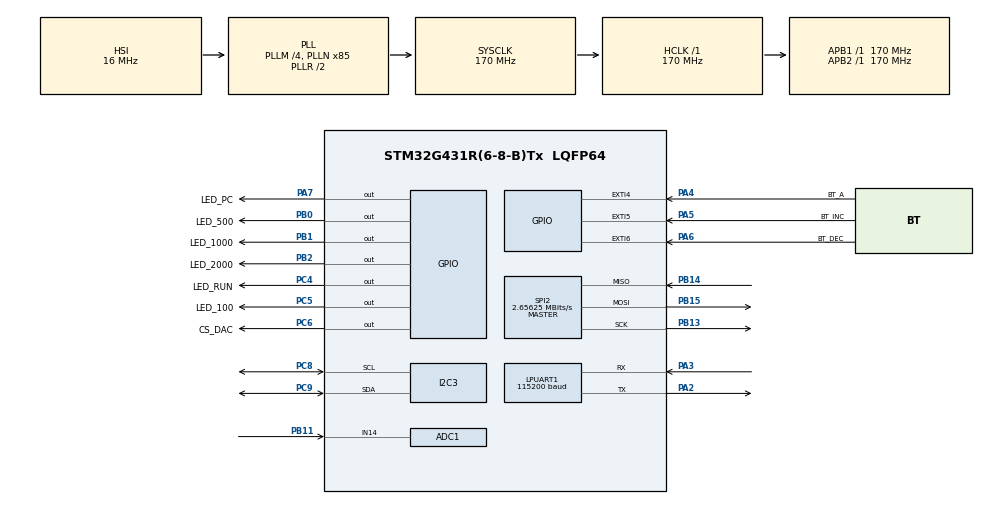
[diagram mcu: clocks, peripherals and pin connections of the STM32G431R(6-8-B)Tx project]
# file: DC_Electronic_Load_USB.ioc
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Mcu.Family=STM32G4
VP_SYS_VS_tim6.Mode=TIM6
RCC.CortexFreq_Value=170000000
SPI2.VirtualType=VM_MASTER
NVIC.TIM6_DAC_IRQn=true\:0\:0\:false\:false\:true\:false\:false\:true
Dma.LPUART1_TX.0.Mode=DMA_NORMAL
PC6.GPIO_Label=CS_DAC
PA6.GPIO_Label=BT_DEC
PB0.GPIO_Label=LED_500
PB11.Signal=ADC1_IN14
PB15.Signal=SPI2_MOSI
PB13.Signal=SPI2_SCK
Dma.LPUART1_TX.0.SyncPolarity=HAL_DMAMUX_SYNC_NO_EVENT
RCC.SYSCLKSource=RCC_SYSCLKSOURCE_PLLCLK
ProjectManager.StackSize=0x400
VP_FREERTOS_VS_CMSIS_V2.Mode=CMSIS_V2
Dma.LPUART1_TX.0.PeriphDataAlignment=DMA_PDATAALIGN_BYTE
Dma.LPUART1_TX.0.Direction=DMA_MEMORY_TO_PERIPH
NVIC.LPUART1_IRQn=true\:5\:0\:false\:false\:true\:true\:true\:true
RCC.HCLKFreq_Value=170000000
RCC.APB2TimFreq_Value=170000000
RCC.AHBFreq_Value=170000000
SPI2.BaudRatePrescaler=SPI_BAUDRATEPRESCALER_64
ADC1.Channel-0\#ChannelRegularConversion=ADC_CHANNEL_14
RCC.HSE_VALUE=8000000
Dma.LPUART1_TX.0.Polarity=HAL_DMAMUX_REQ_GEN_RISING
PB2.Signal=GPIO_Output
PB3.Mode=Trace_Asynchronous_SW
Dma.LPUART1_TX.0.MemInc=DMA_MINC_ENABLE
RCC.ADC12Freq_Value=170000000
PC14-OSC32_IN.Mode=LSE-External-Oscillator
PC4.GPIO_Label=LED_RUN
PA14.Mode=Trace_Asynchronous_SW
PB14.Mode=Full_Duplex_Master
PB1.GPIO_Label=LED_1000
PC9.Mode=I2C
SPI2.CalculateBaudRate=2.65625 MBits/s
VP_SYS_VS_DBSignals.Mode=DisableDeadBatterySignals
Dma.LPUART1_TX.0.Priority=DMA_PRIORITY_LOW
Dma.LPUART1_TX.0.SyncEnable=DISABLE
ADC1.SamplingTime-0\#ChannelRegularConversion=ADC_SAMPLETIME_2CYCLES_5
FREERTOS.configTOTAL_HEAP_SIZE=16384
Dma.LPUART1_TX.0.PeriphInc=DMA_PINC_DISABLE
Mcu.Package=LQFP64
PB1.Signal=GPIO_Output
PA6.Signal=GPXTI6
NVIC.TimeBase=TIM6_DAC_IRQn
SPI2.Mode=SPI_MODE_MASTER
NVIC.TimeBaseIP=TIM6
I2C3.Timing=0x30A0A7FB
RCC.APB1TimFreq_Value=170000000
FREERTOS.configUSE_TICK_HOOK=0
SPI2.Direction=SPI_DIRECTION_2LINES
PC5.Signal=GPIO_Output
PB13.Mode=Full_Duplex_Master
FREERTOS.configMAX_TASK_NAME_LEN=32
Dma.Request0=LPUART1_TX
PA4.GPIO_Label=BT_A
Dma.LPUART1_TX.0.SignalID=NONE
RCC.HSI48_VALUE=48000000
PA3.Signal=LPUART1_RX
Dma.LPUART1_TX.0.Instance=DMA1_Channel1
PC15-OSC32_OUT.Mode=LSE-External-Oscillator
NVIC.EXTI4_IRQn=true\:5\:0\:false\:false\:true\:true\:true\:true
PA5.GPIO_ModeDefaultEXTI=GPIO_MODE_IT_FALLING
PA6.GPIO_ModeDefaultEXTI=GPIO_MODE_IT_FALLING
FREERTOS.Tasks01=defaultTask,24,128,StartDefaultTask,As weak,NULL,Dynamic,NULL,NULL
ADC1.Rank-0\#ChannelRegularConversion=1
ADC1.OffsetNumber-0\#ChannelRegularConversion=ADC_OFFSET_NONE
PC8.Signal=I2C3_SCL
PC4.Signal=GPIO_Output
PC6.Signal=GPIO_Output
RCC.EXTERNAL_CLOCK_VALUE=12288000
PC14-OSC32_IN.Signal=RCC_OSC32_IN
Dma.LPUART1_TX.0.SyncSignalID=NONE
Dma.LPUART1_TX.0.RequestNumber=1
PA13.Signal=SYS_JTMS-SWDIO
PA3.Mode=Asynchronous
Dma.LPUART1_TX.0.EventEnable=DISABLE
PB11.Mode=IN14-Single-Ended
FREERTOS.configRECORD_STACK_HIGH_ADDRESS=1
ProjectManager.TargetToolchain=STM32CubeIDE
Dma.LPUART1_TX.0.SyncRequestNumber=1
PA4.GPIO_ModeDefaultEXTI=GPIO_MODE_IT_FALLING
RCC.USBFreq_Value=170000000
PC15-OSC32_OUT.Signal=RCC_OSC32_OUT
Dma.LPUART1_TX.0.MemDataAlignment=DMA_MDATAALIGN_BYTE
PB14.Signal=SPI2_MISO
PA5.Signal=GPXTI5
board=custom
RCC.VCOOutputFreq_Value=340000000
PB15.Mode=Full_Duplex_Master
RCC.APB2Freq_Value=170000000
PA13.Mode=Trace_Asynchronous_SW
Mcu.Name=STM32G431R(6-8-B)Tx
LPUART1.BaudRate=115200
PA2.Signal=LPUART1_TX
PC8.Mode=I2C
PB3.Signal=SYS_JTDO-SWO
PA4.Signal=GPXTI4
RCC.SYSCLKFreq_VALUE=170000000
PA7.GPIO_Label=LED_PC
ADC1.master=1
PA5.GPIO_Label=BT_INC
PC5.GPIO_Label=LED_100
NVIC.EXTI9_5_IRQn=true\:5\:0\:true\:false\:true\:true\:true\:true
PA14.Signal=SYS_JTCK-SWCLK
PB2.GPIO_Label=LED_2000
ProjectManager.HeapSize=0x200
RCC.HSI_VALUE=16000000
NVIC.PriorityGroup=NVIC_PRIORITYGROUP_4
ADC1.NbrOfConversionFlag=1
RCC.PLLM=RCC_PLLM_DIV4
RCC.PLLN=85
PA2.Mode=Asynchronous
SPI2.DataSize=SPI_DATASIZE_8BIT
PC9.Signal=I2C3_SDA
NVIC.DMA1_Channel1_IRQn=true\:5\:0\:false\:false\:true\:true\:false\:true
RCC.APB1Freq_Value=170000000
PB0.Signal=GPIO_Output
PA7.Signal=GPIO_Output

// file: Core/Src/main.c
/* USER CODE BEGIN Header */
/**
  ******************************************************************************
  * @file           : main.c
  * @brief          : Main program body
  ******************************************************************************
  * @attention
  *
  * <h2><center>&copy; Copyright (c) 2021 STMicroelectronics.
  * All rights reserved.</center></h2>
  *
  * This software component is licensed by ST under BSD 3-Clause license,
  * the "License"; You may not use this file except in compliance with the
  * License. You may obtain a copy of the License at:
  *                        opensource.org/licenses/BSD-3-Clause
  *
  ******************************************************************************
  */
/* USER CODE END Header */
#include "main.h"
#include "cmsis_os.h"

/* USER CODE BEGIN Includes */
#include "APP_Task.h"
/* USER CODE END Includes */

ADC_HandleTypeDef hadc1;

I2C_HandleTypeDef hi2c3;

UART_HandleTypeDef hlpuart1;
DMA_HandleTypeDef hdma_lpuart1_tx;

SPI_HandleTypeDef hspi2;

/* Definitions for defaultTask */
osThreadId_t defaultTaskHandle;
const osThreadAttr_t defaultTask_attributes = {
  .name = "defaultTask",
  .priority = (osPriority_t) osPriorityNormal,
  .stack_size = 128 * 4
};

void SystemClock_Config(void);
static void MX_GPIO_Init(void);
static void MX_DMA_Init(void);
static void MX_LPUART1_UART_Init(void);
static void MX_ADC1_Init(void);
static void MX_SPI2_Init(void);
static void MX_I2C3_Init(void);
void StartDefaultTask(void *argument);

int main(void)
{

  /* MCU Configuration--------------------------------------------------------*/

  /* Reset of all peripherals, Initializes the Flash interface and the Systick. */
  HAL_Init();

  /* Configure the system clock */
  SystemClock_Config();

  /* Initialize all configured peripherals */
  MX_GPIO_Init();
  MX_DMA_Init();
  MX_LPUART1_UART_Init();
  MX_ADC1_Init();
  MX_SPI2_Init();
  MX_I2C3_Init();

  /* Init scheduler */
  osKernelInitialize();

  /* Create the thread(s) */
  /* creation of defaultTask */
  defaultTaskHandle = osThreadNew(StartDefaultTask, NULL, &defaultTask_attributes);

  /* USER CODE BEGIN RTOS_THREADS */
  /* add threads, ... */
  mutex_creation();
  task_creation();
  /* USER CODE END RTOS_THREADS */

  /* Start scheduler */
  osKernelStart();

  /* We should never get here as control is now taken by the scheduler */
  /* Infinite loop */
  while (1)
  {

  }
}

void SystemClock_Config(void)
{
  RCC_OscInitTypeDef RCC_OscInitStruct = {0};
  RCC_ClkInitTypeDef RCC_ClkInitStruct = {0};
  RCC_PeriphCLKInitTypeDef PeriphClkInit = {0};

  /** Configure the main internal regulator output voltage
  */
  HAL_PWREx_ControlVoltageScaling(PWR_REGULATOR_VOLTAGE_SCALE1_BOOST);
  /** Initializes the RCC Oscillators according to the specified parameters
  * in the RCC_OscInitTypeDef structure.
  */
  RCC_OscInitStruct.OscillatorType = RCC_OSCILLATORTYPE_HSI;
  RCC_OscInitStruct.HSIState = RCC_HSI_ON;
  RCC_OscInitStruct.HSICalibrationValue = RCC_HSICALIBRATION_DEFAULT;
  RCC_OscInitStruct.PLL.PLLState = RCC_PLL_ON;
  RCC_OscInitStruct.PLL.PLLSource = RCC_PLLSOURCE_HSI;
  RCC_OscInitStruct.PLL.PLLM = RCC_PLLM_DIV4;
  RCC_OscInitStruct.PLL.PLLN = 85;
  RCC_OscInitStruct.PLL.PLLP = RCC_PLLP_DIV2;
  RCC_OscInitStruct.PLL.PLLQ = RCC_PLLQ_DIV2;
  RCC_OscInitStruct.PLL.PLLR = RCC_PLLR_DIV2;
  if (HAL_RCC_OscConfig(&RCC_OscInitStruct) != HAL_OK)
  {
    Error_Handler();
  }
  /** Initializes the CPU, AHB and APB buses clocks
  */
  RCC_ClkInitStruct.ClockType = RCC_CLOCKTYPE_HCLK|RCC_CLOCKTYPE_SYSCLK
                              |RCC_CLOCKTYPE_PCLK1|RCC_CLOCKTYPE_PCLK2;
  RCC_ClkInitStruct.SYSCLKSource = RCC_SYSCLKSOURCE_PLLCLK;
  RCC_ClkInitStruct.AHBCLKDivider = RCC_SYSCLK_DIV1;
  RCC_ClkInitStruct.APB1CLKDivider = RCC_HCLK_DIV1;
  RCC_ClkInitStruct.APB2CLKDivider = RCC_HCLK_DIV1;

  if (HAL_RCC_ClockConfig(&RCC_ClkInitStruct, FLASH_LATENCY_4) != HAL_OK)
  {
    Error_Handler();
  }
  /** Initializes the peripherals clocks
  */
  PeriphClkInit.PeriphClockSelection = RCC_PERIPHCLK_LPUART1|RCC_PERIPHCLK_I2C3
                              |RCC_PERIPHCLK_ADC12;
  PeriphClkInit.Lpuart1ClockSelection = RCC_LPUART1CLKSOURCE_PCLK1;
  PeriphClkInit.I2c3ClockSelection = RCC_I2C3CLKSOURCE_PCLK1;
  PeriphClkInit.Adc12ClockSelection = RCC_ADC12CLKSOURCE_SYSCLK;
  if (HAL_RCCEx_PeriphCLKConfig(&PeriphClkInit) != HAL_OK)
  {
    Error_Handler();
  }
}

static void MX_ADC1_Init(void)
{

  ADC_MultiModeTypeDef multimode = {0};
  ADC_ChannelConfTypeDef sConfig = {0};

  /** Common config
  */
  hadc1.Instance = ADC1;
  hadc1.Init.ClockPrescaler = ADC_CLOCK_SYNC_PCLK_DIV4;
  hadc1.Init.Resolution = ADC_RESOLUTION_12B;
  hadc1.Init.DataAlign = ADC_DATAALIGN_RIGHT;
  hadc1.Init.GainCompensation = 0;
  hadc1.Init.ScanConvMode = ADC_SCAN_DISABLE;
  hadc1.Init.EOCSelection = ADC_EOC_SINGLE_CONV;
  hadc1.Init.LowPowerAutoWait = DISABLE;
  hadc1.Init.ContinuousConvMode = DISABLE;
  hadc1.Init.NbrOfConversion = 1;
  hadc1.Init.DiscontinuousConvMode = DISABLE;
  hadc1.Init.ExternalTrigConv = ADC_SOFTWARE_START;
  hadc1.Init.ExternalTrigConvEdge = ADC_EXTERNALTRIGCONVEDGE_NONE;
  hadc1.Init.DMAContinuousRequests = DISABLE;
  hadc1.Init.Overrun = ADC_OVR_DATA_PRESERVED;
  hadc1.Init.OversamplingMode = DISABLE;
  if (HAL_ADC_Init(&hadc1) != HAL_OK)
  {
    Error_Handler();
  }
  /** Configure the ADC multi-mode
  */
  multimode.Mode = ADC_MODE_INDEPENDENT;
  if (HAL_ADCEx_MultiModeConfigChannel(&hadc1, &multimode) != HAL_OK)
  {
    Error_Handler();
  }
  /** Configure Regular Channel
  */
  sConfig.Channel = ADC_CHANNEL_14;
  sConfig.Rank = ADC_REGULAR_RANK_1;
  sConfig.SamplingTime = ADC_SAMPLETIME_2CYCLES_5;
  sConfig.SingleDiff = ADC_SINGLE_ENDED;
  sConfig.OffsetNumber = ADC_OFFSET_NONE;
  sConfig.Offset = 0;
  if (HAL_ADC_ConfigChannel(&hadc1, &sConfig) != HAL_OK)
  {
    Error_Handler();
  }

}

static void MX_I2C3_Init(void)
{

  hi2c3.Instance = I2C3;
  hi2c3.Init.Timing = 0x30A0A7FB;
  hi2c3.Init.OwnAddress1 = 0;
  hi2c3.Init.AddressingMode = I2C_ADDRESSINGMODE_7BIT;
  hi2c3.Init.DualAddressMode = I2C_DUALADDRESS_DISABLE;
  hi2c3.Init.OwnAddress2 = 0;
  hi2c3.Init.OwnAddress2Masks = I2C_OA2_NOMASK;
  hi2c3.Init.GeneralCallMode = I2C_GENERALCALL_DISABLE;
  hi2c3.Init.NoStretchMode = I2C_NOSTRETCH_DISABLE;
  if (HAL_I2C_Init(&hi2c3) != HAL_OK)
  {
    Error_Handler();
  }
  /** Configure Analogue filter
  */
  if (HAL_I2CEx_ConfigAnalogFilter(&hi2c3, I2C_ANALOGFILTER_ENABLE) != HAL_OK)
  {
    Error_Handler();
  }
  /** Configure Digital filter
  */
  if (HAL_I2CEx_ConfigDigitalFilter(&hi2c3, 0) != HAL_OK)
  {
    Error_Handler();
  }

}

static void MX_LPUART1_UART_Init(void)
{

  hlpuart1.Instance = LPUART1;
  hlpuart1.Init.BaudRate = 115200;
  hlpuart1.Init.WordLength = UART_WORDLENGTH_8B;
  hlpuart1.Init.StopBits = UART_STOPBITS_1;
  hlpuart1.Init.Parity = UART_PARITY_NONE;
  hlpuart1.Init.Mode = UART_MODE_TX_RX;
  hlpuart1.Init.HwFlowCtl = UART_HWCONTROL_NONE;
  hlpuart1.Init.OneBitSampling = UART_ONE_BIT_SAMPLE_DISABLE;
  hlpuart1.Init.ClockPrescaler = UART_PRESCALER_DIV1;
  hlpuart1.AdvancedInit.AdvFeatureInit = UART_ADVFEATURE_NO_INIT;
  if (HAL_UART_Init(&hlpuart1) != HAL_OK)
  {
    Error_Handler();
  }
  if (HAL_UARTEx_SetTxFifoThreshold(&hlpuart1, UART_TXFIFO_THRESHOLD_1_8) != HAL_OK)
  {
    Error_Handler();
  }
  if (HAL_UARTEx_SetRxFifoThreshold(&hlpuart1, UART_RXFIFO_THRESHOLD_1_8) != HAL_OK)
  {
    Error_Handler();
  }
  if (HAL_UARTEx_DisableFifoMode(&hlpuart1) != HAL_OK)
  {
    Error_Handler();
  }

}

static void MX_SPI2_Init(void)
{

  /* SPI2 parameter configuration*/
  hspi2.Instance = SPI2;
  hspi2.Init.Mode = SPI_MODE_MASTER;
  hspi2.Init.Direction = SPI_DIRECTION_2LINES;
  hspi2.Init.DataSize = SPI_DATASIZE_8BIT;
  hspi2.Init.CLKPolarity = SPI_POLARITY_LOW;
  hspi2.Init.CLKPhase = SPI_PHASE_1EDGE;
  hspi2.Init.NSS = SPI_NSS_SOFT;
  hspi2.Init.BaudRatePrescaler = SPI_BAUDRATEPRESCALER_64;
  hspi2.Init.FirstBit = SPI_FIRSTBIT_MSB;
  hspi2.Init.TIMode = SPI_TIMODE_DISABLE;
  hspi2.Init.CRCCalculation = SPI_CRCCALCULATION_DISABLE;
  hspi2.Init.CRCPolynomial = 7;
  hspi2.Init.CRCLength = SPI_CRC_LENGTH_DATASIZE;
  hspi2.Init.NSSPMode = SPI_NSS_PULSE_ENABLE;
  if (HAL_SPI_Init(&hspi2) != HAL_OK)
  {
    Error_Handler();
  }

}

static void MX_DMA_Init(void)
{

  /* DMA controller clock enable */
  __HAL_RCC_DMAMUX1_CLK_ENABLE();
  __HAL_RCC_DMA1_CLK_ENABLE();

  /* DMA interrupt init */
  /* DMA1_Channel1_IRQn interrupt configuration */
  HAL_NVIC_SetPriority(DMA1_Channel1_IRQn, 5, 0);
  HAL_NVIC_EnableIRQ(DMA1_Channel1_IRQn);

}

static void MX_GPIO_Init(void)
{
  GPIO_InitTypeDef GPIO_InitStruct = {0};

  /* GPIO Ports Clock Enable */
  __HAL_RCC_GPIOC_CLK_ENABLE();
  __HAL_RCC_GPIOA_CLK_ENABLE();
  __HAL_RCC_GPIOB_CLK_ENABLE();

  /*Configure GPIO pin Output Level */
  HAL_GPIO_WritePin(LED_PC_GPIO_Port, LED_PC_Pin, GPIO_PIN_RESET);

  /*Configure GPIO pin Output Level */
  HAL_GPIO_WritePin(GPIOC, LED_RUN_Pin|LED_100_Pin|CS_DAC_Pin, GPIO_PIN_RESET);

  /*Configure GPIO pin Output Level */
  HAL_GPIO_WritePin(GPIOB, LED_500_Pin|LED_1000_Pin|LED_2000_Pin, GPIO_PIN_RESET);

  /*Configure GPIO pins : BT_A_Pin BT_INC_Pin BT_DEC_Pin */
  GPIO_InitStruct.Pin = BT_A_Pin|BT_INC_Pin|BT_DEC_Pin;
  GPIO_InitStruct.Mode = GPIO_MODE_IT_FALLING;
  GPIO_InitStruct.Pull = GPIO_NOPULL;
  HAL_GPIO_Init(GPIOA, &GPIO_InitStruct);

  /*Configure GPIO pin : LED_PC_Pin */
  GPIO_InitStruct.Pin = LED_PC_Pin;
  GPIO_InitStruct.Mode = GPIO_MODE_OUTPUT_PP;
  GPIO_InitStruct.Pull = GPIO_NOPULL;
  GPIO_InitStruct.Speed = GPIO_SPEED_FREQ_LOW;
  HAL_GPIO_Init(LED_PC_GPIO_Port, &GPIO_InitStruct);

  /*Configure GPIO pins : LED_RUN_Pin LED_100_Pin CS_DAC_Pin */
  GPIO_InitStruct.Pin = LED_RUN_Pin|LED_100_Pin|CS_DAC_Pin;
  GPIO_InitStruct.Mode = GPIO_MODE_OUTPUT_PP;
  GPIO_InitStruct.Pull = GPIO_NOPULL;
  GPIO_InitStruct.Speed = GPIO_SPEED_FREQ_LOW;
  HAL_GPIO_Init(GPIOC, &GPIO_InitStruct);

  /*Configure GPIO pins : LED_500_Pin LED_1000_Pin LED_2000_Pin */
  GPIO_InitStruct.Pin = LED_500_Pin|LED_1000_Pin|LED_2000_Pin;
  GPIO_InitStruct.Mode = GPIO_MODE_OUTPUT_PP;
  GPIO_InitStruct.Pull = GPIO_NOPULL;
  GPIO_InitStruct.Speed = GPIO_SPEED_FREQ_LOW;
  HAL_GPIO_Init(GPIOB, &GPIO_InitStruct);

  /* EXTI interrupt init*/
  HAL_NVIC_SetPriority(EXTI4_IRQn, 5, 0);
  HAL_NVIC_EnableIRQ(EXTI4_IRQn);

  HAL_NVIC_SetPriority(EXTI9_5_IRQn, 5, 0);
  HAL_NVIC_EnableIRQ(EXTI9_5_IRQn);

}

__weak void StartDefaultTask(void *argument)
{
  for(;;)
  {
    osDelay(1);
  }
}

 /**
  * @brief  Period elapsed callback in non blocking mode
  * @note   This function is called  when TIM6 interrupt took place, inside
  * HAL_TIM_IRQHandler(). It makes a direct call to HAL_IncTick() to increment
  * a global variable "uwTick" used as application time base.
  * @param  htim : TIM handle
  * @retval None
  */
void HAL_TIM_PeriodElapsedCallback(TIM_HandleTypeDef *htim)
{
  if (htim->Instance == TIM6) {
    HAL_IncTick();
  }
}

void Error_Handler(void)
{
  __disable_irq();
  while (1)
  {
  }
}

/************************ (C) COPYRIGHT STMicroelectronics *****END OF FILE****/
